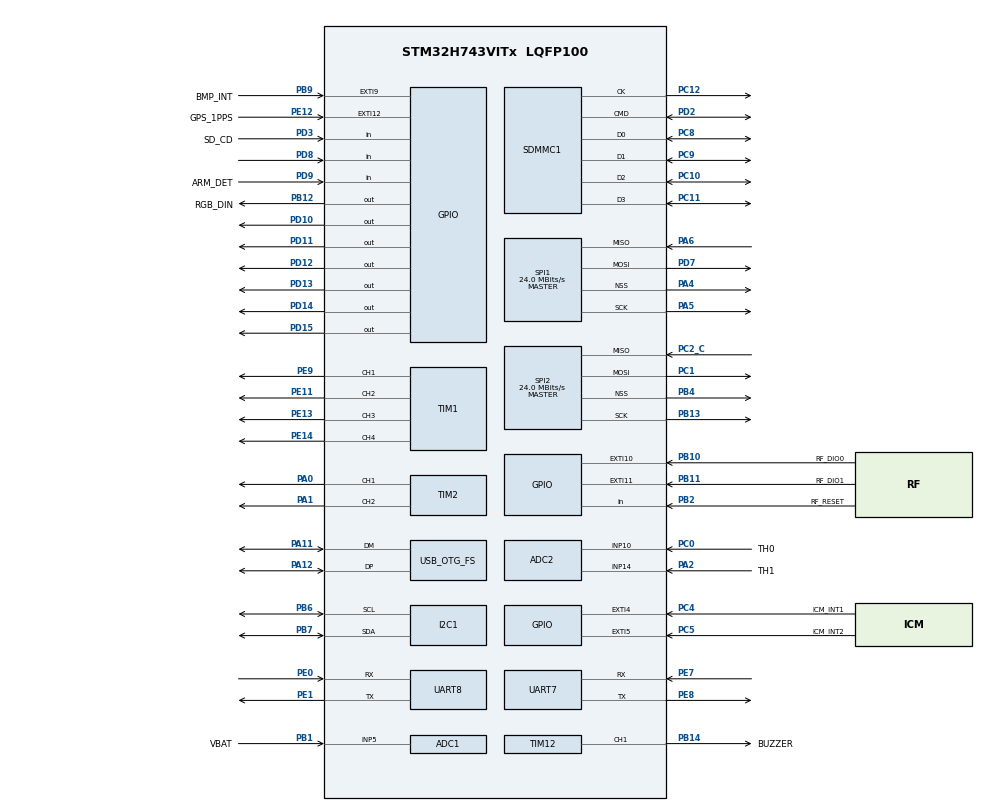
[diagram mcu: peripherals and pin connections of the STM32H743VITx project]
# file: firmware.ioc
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ADC1.Channel-2\#ChannelRegularConversion=ADC_CHANNEL_5
ADC1.ClockPrescaler=ADC_CLOCK_ASYNC_DIV4
ADC1.NbrOfConversionFlag=1
ADC1.OffsetNumber-2\#ChannelRegularConversion=ADC_OFFSET_NONE
ADC1.OffsetSignedSaturation-2\#ChannelRegularConversion=DISABLE
ADC1.Rank-2\#ChannelRegularConversion=1
ADC1.SamplingTime-2\#ChannelRegularConversion=ADC_SAMPLETIME_1CYCLE_5
ADC1.master=1
ADC2.Channel-3\#ChannelRegularConversion=ADC_CHANNEL_10
ADC2.ClockPrescaler=ADC_CLOCK_ASYNC_DIV4
ADC2.NbrOfConversionFlag=1
ADC2.OffsetNumber-3\#ChannelRegularConversion=ADC_OFFSET_NONE
ADC2.OffsetSignedSaturation-3\#ChannelRegularConversion=DISABLE
ADC2.Rank-3\#ChannelRegularConversion=1
ADC2.SamplingTime-3\#ChannelRegularConversion=ADC_SAMPLETIME_1CYCLE_5
CORTEX_M7.default_mode_Activation=1
FATFS.BSP.number=1
FATFS0.BSP.STBoard=false
FATFS0.BSP.api=Unknown
FATFS0.BSP.instance=PD3
FATFS0.BSP.ip=GPIO
FATFS0.BSP.mode=Input
FATFS0.BSP.name=Detect_SDIO
FATFS0.BSP.solution=PD3
I2C1.Timing=0x00707CBB
Mcu.Family=STM32H7
Mcu.Name=STM32H743VITx
Mcu.Package=LQFP100
NVIC.OTG_FS_IRQn=true\:0\:0\:false\:false\:true\:false\:true\:true
NVIC.PriorityGroup=NVIC_PRIORITYGROUP_4
PA0.Signal=S_TIM2_CH1_ETR
PA1.Signal=S_TIM2_CH2
PA11.Mode=Device_Only
PA11.Signal=USB_OTG_FS_DM
PA12.Mode=Device_Only
PA12.Signal=USB_OTG_FS_DP
PA13\ (JTMS/SWDIO).Signal=DEBUG_JTMS-SWDIO
PA14\ (JTCK/SWCLK).Signal=DEBUG_JTCK-SWCLK
PA2.GPIO_Label=TH1
PA2.Signal=ADCx_INP14
PA4.Mode=NSS_Signal_Hard_Output
PA4.Signal=SPI1_NSS
PA5.Mode=Full_Duplex_Master
PA5.Signal=SPI1_SCK
PA6.Mode=Full_Duplex_Master
PA6.Signal=SPI1_MISO
PB1.GPIO_Label=VBAT
PB1.Signal=ADCx_INP5
PB10.GPIO_Label=RF_DIO0
PB10.Signal=GPXTI10
PB11.GPIO_Label=RF_DIO1
PB11.Signal=GPXTI11
PB12.GPIO_Label=RGB_DIN
PB12.Signal=GPIO_Output
PB13.Mode=Full_Duplex_Master
PB13.Signal=SPI2_SCK
PB14.GPIO_Label=BUZZER
PB14.Signal=S_TIM12_CH1
PB2.GPIO_Label=RF_RESET
PB2.Signal=GPIO_Input
PB4\ (NJTRST).Mode=NSS_Signal_Hard_Output
PB4\ (NJTRST).Signal=SPI2_NSS
PB6.Mode=I2C
PB6.Signal=I2C1_SCL
PB7.Mode=I2C
PB7.Signal=I2C1_SDA
PB9.GPIO_Label=BMP_INT
PB9.Signal=GPXTI9
PC0.GPIO_Label=TH0
PC0.Signal=ADCx_INP10
PC1.Mode=Full_Duplex_Master
PC1.Signal=SPI2_MOSI
PC10.Mode=SD_4_bits_Wide_bus
PC10.Signal=SDMMC1_D2
PC11.Mode=SD_4_bits_Wide_bus
PC11.Signal=SDMMC1_D3
PC12.Mode=SD_4_bits_Wide_bus
PC12.Signal=SDMMC1_CK
PC14-OSC32_IN\ (OSC32_IN).Mode=LSE-External-Oscillator
PC14-OSC32_IN\ (OSC32_IN).Signal=RCC_OSC32_IN
PC15-OSC32_OUT\ (OSC32_OUT).Mode=LSE-External-Oscillator
PC15-OSC32_OUT\ (OSC32_OUT).Signal=RCC_OSC32_OUT
PC2_C.Mode=Full_Duplex_Master
PC2_C.Signal=SPI2_MISO
PC4.GPIO_Label=ICM_INT1
PC4.Signal=GPXTI4
PC5.GPIO_Label=ICM_INT2
PC5.Signal=GPXTI5
PC8.Mode=SD_4_bits_Wide_bus
PC8.Signal=SDMMC1_D0
PC9.Mode=SD_4_bits_Wide_bus
PC9.Signal=SDMMC1_D1
PD10.Signal=GPIO_Output
PD11.Signal=GPIO_Output
PD12.Signal=GPIO_Output
PD13.Signal=GPIO_Output
PD14.Signal=GPIO_Output
PD15.Signal=GPIO_Output
PD2.Mode=SD_4_bits_Wide_bus
PD2.Signal=SDMMC1_CMD
PD3.GPIO_Label=SD_CD
PD3.Signal=GPIO_Input
PD7.Mode=Full_Duplex_Master
PD7.Signal=SPI1_MOSI
PD8.Signal=GPIO_Input
PD9.GPIO_Label=ARM_DET
PD9.Signal=GPIO_Input
PE0.Mode=Asynchronous
PE0.Signal=UART8_RX
PE1.Mode=Asynchronous
PE1.Signal=UART8_TX
PE11.Signal=S_TIM1_CH2
PE12.GPIO_Label=GPS_1PPS
PE12.Signal=GPXTI12
PE13.Signal=S_TIM1_CH3
PE14.Signal=S_TIM1_CH4
PE7.Mode=Asynchronous
PE7.Signal=UART7_RX
PE8.Mode=Asynchronous
PE8.Signal=UART7_TX
PE9.Signal=S_TIM1_CH1
PH0-OSC_IN\ (PH0).Mode=HSE-External-Oscillator
PH0-OSC_IN\ (PH0).Signal=RCC_OSC_IN
PH1-OSC_OUT\ (PH1).Mode=HSE-External-Oscillator
PH1-OSC_OUT\ (PH1).Signal=RCC_OSC_OUT
ProjectManager.HeapSize=0x200
ProjectManager.StackSize=0x400
ProjectManager.TargetToolchain=Makefile
RCC.ADCFreq_Value=75000000
RCC.APB1Freq_Value=32000000
RCC.APB2Freq_Value=64000000
RCC.APB3Freq_Value=64000000
RCC.APB4Freq_Value=64000000
RCC.CortexFreq_Value=64000000
RCC.D2PPRE1=RCC_APB1_DIV2
RCC.DIVM1=5
RCC.DIVM2=2
RCC.DIVN1=48
RCC.DIVN2=12
RCC.DIVQ1=5
RCC.HCLKFreq_Value=64000000
RCC.PLL2FRACN=0
RCC.PLL3FRACN=0
RCC.PLLFRACN=0
RCC.SYSCLKFreq_VALUE=64000000
RCC.USBFreq_Value=48000000
SH.ADCx_INP10.0=ADC2_INP10,IN10-Single-Ended
SH.ADCx_INP10.1=ADC1_INP10
SH.ADCx_INP14.0=ADC2_INP14,IN14-Single-Ended
SH.ADCx_INP5.0=ADC1_INP5,IN5-Single-Ended
SH.S_TIM12_CH1.0=TIM12_CH1,PWM Generation1 CH1
SH.S_TIM1_CH1.0=TIM1_CH1,PWM Generation1 CH1
SH.S_TIM1_CH2.0=TIM1_CH2,PWM Generation2 CH2
SH.S_TIM1_CH3.0=TIM1_CH3,PWM Generation3 CH3
SH.S_TIM1_CH4.0=TIM1_CH4,PWM Generation4 CH4
SH.S_TIM2_CH1_ETR.0=TIM2_CH1,PWM Generation1 CH1
SH.S_TIM2_CH2.0=TIM2_CH2,PWM Generation2 CH2
SPI1.CalculateBaudRate=24.0 MBits/s
SPI1.Direction=SPI_DIRECTION_2LINES
SPI1.Mode=SPI_MODE_MASTER
SPI1.VirtualNSS=VM_NSSHARD
SPI1.VirtualType=VM_MASTER
SPI2.CalculateBaudRate=24.0 MBits/s
SPI2.Direction=SPI_DIRECTION_2LINES
SPI2.Mode=SPI_MODE_MASTER
SPI2.VirtualNSS=VM_NSSHARD
SPI2.VirtualType=VM_MASTER
TIM1.Channel-PWM\ Generation1\ CH1=TIM_CHANNEL_1
TIM1.Channel-PWM\ Generation2\ CH2=TIM_CHANNEL_2
TIM1.Channel-PWM\ Generation3\ CH3=TIM_CHANNEL_3
TIM1.Channel-PWM\ Generation4\ CH4=TIM_CHANNEL_4
TIM12.Channel-PWM\ Generation1\ CH1=TIM_CHANNEL_1
TIM2.Channel-PWM\ Generation1\ CH1=TIM_CHANNEL_1
TIM2.Channel-PWM\ Generation2\ CH2=TIM_CHANNEL_2
USB_DEVICE.CLASS_NAME_FS=CDC
USB_DEVICE.VirtualMode-CDC_FS=Cdc
USB_DEVICE.VirtualModeFS=Cdc_FS
USB_OTG_FS.VirtualMode=Device_Only
VP_FATFS_VS_SDIO.Mode=SDIO
VP_MEMORYMAP_VS_MEMORYMAP.Mode=CurAppReg
VP_TIM1_VS_ClockSourceINT.Mode=Internal
VP_TIM2_VS_ClockSourceINT.Mode=Internal
VP_USB_DEVICE_VS_USB_DEVICE_CDC_FS.Mode=CDC_FS
board=custom

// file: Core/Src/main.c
/* USER CODE BEGIN Header */
/**
  ******************************************************************************
  * @file           : main.c
  * @brief          : Main program body
  ******************************************************************************
  * @attention
  *
  * Copyright (c) 2025 STMicroelectronics.
  * All rights reserved.
  *
  * This software is licensed under terms that can be found in the LICENSE file
  * in the root directory of this software component.
  * If no LICENSE file comes with this software, it is provided AS-IS.
  *
  ******************************************************************************
  */
/* USER CODE END Header */
#include "main.h"
#include "fatfs.h"
#include "usb_device.h"

/* USER CODE BEGIN Includes */
#include "logging.h"

/* USER CODE END Includes */

ADC_HandleTypeDef hadc1;
ADC_HandleTypeDef hadc2;

I2C_HandleTypeDef hi2c1;

SD_HandleTypeDef hsd1;

SPI_HandleTypeDef hspi1;
SPI_HandleTypeDef hspi2;

TIM_HandleTypeDef htim1;
TIM_HandleTypeDef htim2;
TIM_HandleTypeDef htim12;

UART_HandleTypeDef huart7;
UART_HandleTypeDef huart8;

void SystemClock_Config(void);
void PeriphCommonClock_Config(void);
static void MPU_Config(void);
static void MX_GPIO_Init(void);
static void MX_I2C1_Init(void);
static void MX_SDMMC1_SD_Init(void);
static void MX_SPI1_Init(void);
static void MX_SPI2_Init(void);
static void MX_TIM1_Init(void);
static void MX_TIM2_Init(void);
static void MX_TIM12_Init(void);
static void MX_UART7_Init(void);
static void MX_UART8_Init(void);
static void MX_ADC1_Init(void);
static void MX_ADC2_Init(void);

int main(void)
{

  /* MPU Configuration--------------------------------------------------------*/
  MPU_Config();

  /* MCU Configuration--------------------------------------------------------*/

  /* Reset of all peripherals, Initializes the Flash interface and the Systick. */
  HAL_Init();

  /* Configure the system clock */
  SystemClock_Config();

  /* Configure the peripherals common clocks */
  PeriphCommonClock_Config();

  /* Initialize all configured peripherals */
  MX_GPIO_Init();
  MX_I2C1_Init();
  MX_SDMMC1_SD_Init();
  MX_SPI1_Init();
  MX_SPI2_Init();
  MX_TIM1_Init();
  MX_TIM2_Init();
  MX_TIM12_Init();
  MX_UART7_Init();
  MX_UART8_Init();
  MX_ADC1_Init();
  MX_ADC2_Init();
  MX_USB_DEVICE_Init();
  MX_FATFS_Init();
  /* USER CODE BEGIN 2 */
  logging_init();
  /* USER CODE END 2 */

  /* Infinite loop */
  while (1)
  {

  }
}

void SystemClock_Config(void)
{
  RCC_OscInitTypeDef RCC_OscInitStruct = {0};
  RCC_ClkInitTypeDef RCC_ClkInitStruct = {0};

  /** Supply configuration update enable
  */
  HAL_PWREx_ConfigSupply(PWR_LDO_SUPPLY);

  /** Configure the main internal regulator output voltage
  */
  __HAL_PWR_VOLTAGESCALING_CONFIG(PWR_REGULATOR_VOLTAGE_SCALE3);

  while(!__HAL_PWR_GET_FLAG(PWR_FLAG_VOSRDY)) {}

  /** Initializes the RCC Oscillators according to the specified parameters
  * in the RCC_OscInitTypeDef structure.
  */
  RCC_OscInitStruct.OscillatorType = RCC_OSCILLATORTYPE_HSI|RCC_OSCILLATORTYPE_HSE;
  RCC_OscInitStruct.HSEState = RCC_HSE_ON;
  RCC_OscInitStruct.HSIState = RCC_HSI_DIV1;
  RCC_OscInitStruct.HSICalibrationValue = RCC_HSICALIBRATION_DEFAULT;
  RCC_OscInitStruct.PLL.PLLState = RCC_PLL_ON;
  RCC_OscInitStruct.PLL.PLLSource = RCC_PLLSOURCE_HSE;
  RCC_OscInitStruct.PLL.PLLM = 5;
  RCC_OscInitStruct.PLL.PLLN = 48;
  RCC_OscInitStruct.PLL.PLLP = 2;
  RCC_OscInitStruct.PLL.PLLQ = 5;
  RCC_OscInitStruct.PLL.PLLR = 2;
  RCC_OscInitStruct.PLL.PLLRGE = RCC_PLL1VCIRANGE_2;
  RCC_OscInitStruct.PLL.PLLVCOSEL = RCC_PLL1VCOWIDE;
  RCC_OscInitStruct.PLL.PLLFRACN = 0;
  if (HAL_RCC_OscConfig(&RCC_OscInitStruct) != HAL_OK)
  {
    Error_Handler();
  }

  /** Initializes the CPU, AHB and APB buses clocks
  */
  RCC_ClkInitStruct.ClockType = RCC_CLOCKTYPE_HCLK|RCC_CLOCKTYPE_SYSCLK
                              |RCC_CLOCKTYPE_PCLK1|RCC_CLOCKTYPE_PCLK2
                              |RCC_CLOCKTYPE_D3PCLK1|RCC_CLOCKTYPE_D1PCLK1;
  RCC_ClkInitStruct.SYSCLKSource = RCC_SYSCLKSOURCE_HSI;
  RCC_ClkInitStruct.SYSCLKDivider = RCC_SYSCLK_DIV1;
  RCC_ClkInitStruct.AHBCLKDivider = RCC_HCLK_DIV1;
  RCC_ClkInitStruct.APB3CLKDivider = RCC_APB3_DIV1;
  RCC_ClkInitStruct.APB1CLKDivider = RCC_APB1_DIV2;
  RCC_ClkInitStruct.APB2CLKDivider = RCC_APB2_DIV1;
  RCC_ClkInitStruct.APB4CLKDivider = RCC_APB4_DIV1;

  if (HAL_RCC_ClockConfig(&RCC_ClkInitStruct, FLASH_LATENCY_1) != HAL_OK)
  {
    Error_Handler();
  }
}

void PeriphCommonClock_Config(void)
{
  RCC_PeriphCLKInitTypeDef PeriphClkInitStruct = {0};

  /** Initializes the peripherals clock
  */
  PeriphClkInitStruct.PeriphClockSelection = RCC_PERIPHCLK_ADC;
  PeriphClkInitStruct.PLL2.PLL2M = 2;
  PeriphClkInitStruct.PLL2.PLL2N = 12;
  PeriphClkInitStruct.PLL2.PLL2P = 2;
  PeriphClkInitStruct.PLL2.PLL2Q = 2;
  PeriphClkInitStruct.PLL2.PLL2R = 2;
  PeriphClkInitStruct.PLL2.PLL2RGE = RCC_PLL2VCIRANGE_3;
  PeriphClkInitStruct.PLL2.PLL2VCOSEL = RCC_PLL2VCOMEDIUM;
  PeriphClkInitStruct.PLL2.PLL2FRACN = 0;
  PeriphClkInitStruct.AdcClockSelection = RCC_ADCCLKSOURCE_PLL2;
  if (HAL_RCCEx_PeriphCLKConfig(&PeriphClkInitStruct) != HAL_OK)
  {
    Error_Handler();
  }
}

static void MX_ADC1_Init(void)
{

  ADC_MultiModeTypeDef multimode = {0};
  ADC_ChannelConfTypeDef sConfig = {0};

  /** Common config
  */
  hadc1.Instance = ADC1;
  hadc1.Init.ClockPrescaler = ADC_CLOCK_ASYNC_DIV4;
  hadc1.Init.Resolution = ADC_RESOLUTION_16B;
  hadc1.Init.ScanConvMode = ADC_SCAN_DISABLE;
  hadc1.Init.EOCSelection = ADC_EOC_SINGLE_CONV;
  hadc1.Init.LowPowerAutoWait = DISABLE;
  hadc1.Init.ContinuousConvMode = DISABLE;
  hadc1.Init.NbrOfConversion = 1;
  hadc1.Init.DiscontinuousConvMode = DISABLE;
  hadc1.Init.ExternalTrigConv = ADC_SOFTWARE_START;
  hadc1.Init.ExternalTrigConvEdge = ADC_EXTERNALTRIGCONVEDGE_NONE;
  hadc1.Init.ConversionDataManagement = ADC_CONVERSIONDATA_DR;
  hadc1.Init.Overrun = ADC_OVR_DATA_PRESERVED;
  hadc1.Init.LeftBitShift = ADC_LEFTBITSHIFT_NONE;
  hadc1.Init.OversamplingMode = DISABLE;
  hadc1.Init.Oversampling.Ratio = 1;
  if (HAL_ADC_Init(&hadc1) != HAL_OK)
  {
    Error_Handler();
  }

  /** Configure the ADC multi-mode
  */
  multimode.Mode = ADC_MODE_INDEPENDENT;
  if (HAL_ADCEx_MultiModeConfigChannel(&hadc1, &multimode) != HAL_OK)
  {
    Error_Handler();
  }

  /** Configure Regular Channel
  */
  sConfig.Channel = ADC_CHANNEL_5;
  sConfig.Rank = ADC_REGULAR_RANK_1;
  sConfig.SamplingTime = ADC_SAMPLETIME_1CYCLE_5;
  sConfig.SingleDiff = ADC_SINGLE_ENDED;
  sConfig.OffsetNumber = ADC_OFFSET_NONE;
  sConfig.Offset = 0;
  sConfig.OffsetSignedSaturation = DISABLE;
  if (HAL_ADC_ConfigChannel(&hadc1, &sConfig) != HAL_OK)
  {
    Error_Handler();
  }

}

static void MX_ADC2_Init(void)
{

  ADC_ChannelConfTypeDef sConfig = {0};

  /** Common config
  */
  hadc2.Instance = ADC2;
  hadc2.Init.ClockPrescaler = ADC_CLOCK_ASYNC_DIV4;
  hadc2.Init.Resolution = ADC_RESOLUTION_16B;
  hadc2.Init.ScanConvMode = ADC_SCAN_DISABLE;
  hadc2.Init.EOCSelection = ADC_EOC_SINGLE_CONV;
  hadc2.Init.LowPowerAutoWait = DISABLE;
  hadc2.Init.ContinuousConvMode = DISABLE;
  hadc2.Init.NbrOfConversion = 1;
  hadc2.Init.DiscontinuousConvMode = DISABLE;
  hadc2.Init.ExternalTrigConv = ADC_SOFTWARE_START;
  hadc2.Init.ExternalTrigConvEdge = ADC_EXTERNALTRIGCONVEDGE_NONE;
  hadc2.Init.ConversionDataManagement = ADC_CONVERSIONDATA_DR;
  hadc2.Init.Overrun = ADC_OVR_DATA_PRESERVED;
  hadc2.Init.LeftBitShift = ADC_LEFTBITSHIFT_NONE;
  hadc2.Init.OversamplingMode = DISABLE;
  hadc2.Init.Oversampling.Ratio = 1;
  if (HAL_ADC_Init(&hadc2) != HAL_OK)
  {
    Error_Handler();
  }

  /** Configure Regular Channel
  */
  sConfig.Channel = ADC_CHANNEL_10;
  sConfig.Rank = ADC_REGULAR_RANK_1;
  sConfig.SamplingTime = ADC_SAMPLETIME_1CYCLE_5;
  sConfig.SingleDiff = ADC_SINGLE_ENDED;
  sConfig.OffsetNumber = ADC_OFFSET_NONE;
  sConfig.Offset = 0;
  sConfig.OffsetSignedSaturation = DISABLE;
  if (HAL_ADC_ConfigChannel(&hadc2, &sConfig) != HAL_OK)
  {
    Error_Handler();
  }

}

static void MX_I2C1_Init(void)
{

  hi2c1.Instance = I2C1;
  hi2c1.Init.Timing = 0x00707CBB;
  hi2c1.Init.OwnAddress1 = 0;
  hi2c1.Init.AddressingMode = I2C_ADDRESSINGMODE_7BIT;
  hi2c1.Init.DualAddressMode = I2C_DUALADDRESS_DISABLE;
  hi2c1.Init.OwnAddress2 = 0;
  hi2c1.Init.OwnAddress2Masks = I2C_OA2_NOMASK;
  hi2c1.Init.GeneralCallMode = I2C_GENERALCALL_DISABLE;
  hi2c1.Init.NoStretchMode = I2C_NOSTRETCH_DISABLE;
  if (HAL_I2C_Init(&hi2c1) != HAL_OK)
  {
    Error_Handler();
  }

  /** Configure Analogue filter
  */
  if (HAL_I2CEx_ConfigAnalogFilter(&hi2c1, I2C_ANALOGFILTER_ENABLE) != HAL_OK)
  {
    Error_Handler();
  }

  /** Configure Digital filter
  */
  if (HAL_I2CEx_ConfigDigitalFilter(&hi2c1, 0) != HAL_OK)
  {
    Error_Handler();
  }

}

static void MX_SDMMC1_SD_Init(void)
{

  hsd1.Instance = SDMMC1;
  hsd1.Init.ClockEdge = SDMMC_CLOCK_EDGE_RISING;
  hsd1.Init.ClockPowerSave = SDMMC_CLOCK_POWER_SAVE_DISABLE;
  hsd1.Init.BusWide = SDMMC_BUS_WIDE_4B;
  hsd1.Init.HardwareFlowControl = SDMMC_HARDWARE_FLOW_CONTROL_DISABLE;
  hsd1.Init.ClockDiv = 0;
  if (HAL_SD_Init(&hsd1) != HAL_OK)
  {
    Error_Handler();
  }

}

static void MX_SPI1_Init(void)
{

  /* SPI1 parameter configuration*/
  hspi1.Instance = SPI1;
  hspi1.Init.Mode = SPI_MODE_MASTER;
  hspi1.Init.Direction = SPI_DIRECTION_2LINES;
  hspi1.Init.DataSize = SPI_DATASIZE_4BIT;
  hspi1.Init.CLKPolarity = SPI_POLARITY_LOW;
  hspi1.Init.CLKPhase = SPI_PHASE_1EDGE;
  hspi1.Init.NSS = SPI_NSS_HARD_OUTPUT;
  hspi1.Init.BaudRatePrescaler = SPI_BAUDRATEPRESCALER_2;
  hspi1.Init.FirstBit = SPI_FIRSTBIT_MSB;
  hspi1.Init.TIMode = SPI_TIMODE_DISABLE;
  hspi1.Init.CRCCalculation = SPI_CRCCALCULATION_DISABLE;
  hspi1.Init.CRCPolynomial = 0x0;
  hspi1.Init.NSSPMode = SPI_NSS_PULSE_ENABLE;
  hspi1.Init.NSSPolarity = SPI_NSS_POLARITY_LOW;
  hspi1.Init.FifoThreshold = SPI_FIFO_THRESHOLD_01DATA;
  hspi1.Init.TxCRCInitializationPattern = SPI_CRC_INITIALIZATION_ALL_ZERO_PATTERN;
  hspi1.Init.RxCRCInitializationPattern = SPI_CRC_INITIALIZATION_ALL_ZERO_PATTERN;
  hspi1.Init.MasterSSIdleness = SPI_MASTER_SS_IDLENESS_00CYCLE;
  hspi1.Init.MasterInterDataIdleness = SPI_MASTER_INTERDATA_IDLENESS_00CYCLE;
  hspi1.Init.MasterReceiverAutoSusp = SPI_MASTER_RX_AUTOSUSP_DISABLE;
  hspi1.Init.MasterKeepIOState = SPI_MASTER_KEEP_IO_STATE_DISABLE;
  hspi1.Init.IOSwap = SPI_IO_SWAP_DISABLE;
  if (HAL_SPI_Init(&hspi1) != HAL_OK)
  {
    Error_Handler();
  }

}

static void MX_SPI2_Init(void)
{

  /* SPI2 parameter configuration*/
  hspi2.Instance = SPI2;
  hspi2.Init.Mode = SPI_MODE_MASTER;
  hspi2.Init.Direction = SPI_DIRECTION_2LINES;
  hspi2.Init.DataSize = SPI_DATASIZE_4BIT;
  hspi2.Init.CLKPolarity = SPI_POLARITY_LOW;
  hspi2.Init.CLKPhase = SPI_PHASE_1EDGE;
  hspi2.Init.NSS = SPI_NSS_HARD_OUTPUT;
  hspi2.Init.BaudRatePrescaler = SPI_BAUDRATEPRESCALER_2;
  hspi2.Init.FirstBit = SPI_FIRSTBIT_MSB;
  hspi2.Init.TIMode = SPI_TIMODE_DISABLE;
  hspi2.Init.CRCCalculation = SPI_CRCCALCULATION_DISABLE;
  hspi2.Init.CRCPolynomial = 0x0;
  hspi2.Init.NSSPMode = SPI_NSS_PULSE_ENABLE;
  hspi2.Init.NSSPolarity = SPI_NSS_POLARITY_LOW;
  hspi2.Init.FifoThreshold = SPI_FIFO_THRESHOLD_01DATA;
  hspi2.Init.TxCRCInitializationPattern = SPI_CRC_INITIALIZATION_ALL_ZERO_PATTERN;
  hspi2.Init.RxCRCInitializationPattern = SPI_CRC_INITIALIZATION_ALL_ZERO_PATTERN;
  hspi2.Init.MasterSSIdleness = SPI_MASTER_SS_IDLENESS_00CYCLE;
  hspi2.Init.MasterInterDataIdleness = SPI_MASTER_INTERDATA_IDLENESS_00CYCLE;
  hspi2.Init.MasterReceiverAutoSusp = SPI_MASTER_RX_AUTOSUSP_DISABLE;
  hspi2.Init.MasterKeepIOState = SPI_MASTER_KEEP_IO_STATE_DISABLE;
  hspi2.Init.IOSwap = SPI_IO_SWAP_DISABLE;
  if (HAL_SPI_Init(&hspi2) != HAL_OK)
  {
    Error_Handler();
  }

}

static void MX_TIM1_Init(void)
{

  TIM_ClockConfigTypeDef sClockSourceConfig = {0};
  TIM_MasterConfigTypeDef sMasterConfig = {0};
  TIM_OC_InitTypeDef sConfigOC = {0};
  TIM_BreakDeadTimeConfigTypeDef sBreakDeadTimeConfig = {0};

  htim1.Instance = TIM1;
  htim1.Init.Prescaler = 0;
  htim1.Init.CounterMode = TIM_COUNTERMODE_UP;
  htim1.Init.Period = 65535;
  htim1.Init.ClockDivision = TIM_CLOCKDIVISION_DIV1;
  htim1.Init.RepetitionCounter = 0;
  htim1.Init.AutoReloadPreload = TIM_AUTORELOAD_PRELOAD_DISABLE;
  if (HAL_TIM_Base_Init(&htim1) != HAL_OK)
  {
    Error_Handler();
  }
  sClockSourceConfig.ClockSource = TIM_CLOCKSOURCE_INTERNAL;
  if (HAL_TIM_ConfigClockSource(&htim1, &sClockSourceConfig) != HAL_OK)
  {
    Error_Handler();
  }
  if (HAL_TIM_PWM_Init(&htim1) != HAL_OK)
  {
    Error_Handler();
  }
  sMasterConfig.MasterOutputTrigger = TIM_TRGO_RESET;
  sMasterConfig.MasterOutputTrigger2 = TIM_TRGO2_RESET;
  sMasterConfig.MasterSlaveMode = TIM_MASTERSLAVEMODE_DISABLE;
  if (HAL_TIMEx_MasterConfigSynchronization(&htim1, &sMasterConfig) != HAL_OK)
  {
    Error_Handler();
  }
  sConfigOC.OCMode = TIM_OCMODE_PWM1;
  sConfigOC.Pulse = 0;
  sConfigOC.OCPolarity = TIM_OCPOLARITY_HIGH;
  sConfigOC.OCNPolarity = TIM_OCNPOLARITY_HIGH;
  sConfigOC.OCFastMode = TIM_OCFAST_DISABLE;
  sConfigOC.OCIdleState = TIM_OCIDLESTATE_RESET;
  sConfigOC.OCNIdleState = TIM_OCNIDLESTATE_RESET;
  if (HAL_TIM_PWM_ConfigChannel(&htim1, &sConfigOC, TIM_CHANNEL_1) != HAL_OK)
  {
    Error_Handler();
  }
  if (HAL_TIM_PWM_ConfigChannel(&htim1, &sConfigOC, TIM_CHANNEL_2) != HAL_OK)
  {
    Error_Handler();
  }
  if (HAL_TIM_PWM_ConfigChannel(&htim1, &sConfigOC, TIM_CHANNEL_3) != HAL_OK)
  {
    Error_Handler();
  }
  if (HAL_TIM_PWM_ConfigChannel(&htim1, &sConfigOC, TIM_CHANNEL_4) != HAL_OK)
  {
    Error_Handler();
  }
  sBreakDeadTimeConfig.OffStateRunMode = TIM_OSSR_DISABLE;
  sBreakDeadTimeConfig.OffStateIDLEMode = TIM_OSSI_DISABLE;
  sBreakDeadTimeConfig.LockLevel = TIM_LOCKLEVEL_OFF;
  sBreakDeadTimeConfig.DeadTime = 0;
  sBreakDeadTimeConfig.BreakState = TIM_BREAK_DISABLE;
  sBreakDeadTimeConfig.BreakPolarity = TIM_BREAKPOLARITY_HIGH;
  sBreakDeadTimeConfig.BreakFilter = 0;
  sBreakDeadTimeConfig.Break2State = TIM_BREAK2_DISABLE;
  sBreakDeadTimeConfig.Break2Polarity = TIM_BREAK2POLARITY_HIGH;
  sBreakDeadTimeConfig.Break2Filter = 0;
  sBreakDeadTimeConfig.AutomaticOutput = TIM_AUTOMATICOUTPUT_DISABLE;
  if (HAL_TIMEx_ConfigBreakDeadTime(&htim1, &sBreakDeadTimeConfig) != HAL_OK)
  {
    Error_Handler();
  }
  HAL_TIM_MspPostInit(&htim1);

}

static void MX_TIM2_Init(void)
{

  TIM_ClockConfigTypeDef sClockSourceConfig = {0};
  TIM_MasterConfigTypeDef sMasterConfig = {0};
  TIM_OC_InitTypeDef sConfigOC = {0};

  htim2.Instance = TIM2;
  htim2.Init.Prescaler = 0;
  htim2.Init.CounterMode = TIM_COUNTERMODE_UP;
  htim2.Init.Period = 4294967295;
  htim2.Init.ClockDivision = TIM_CLOCKDIVISION_DIV1;
  htim2.Init.AutoReloadPreload = TIM_AUTORELOAD_PRELOAD_DISABLE;
  if (HAL_TIM_Base_Init(&htim2) != HAL_OK)
  {
    Error_Handler();
  }
  sClockSourceConfig.ClockSource = TIM_CLOCKSOURCE_INTERNAL;
  if (HAL_TIM_ConfigClockSource(&htim2, &sClockSourceConfig) != HAL_OK)
  {
    Error_Handler();
  }
  if (HAL_TIM_PWM_Init(&htim2) != HAL_OK)
  {
    Error_Handler();
  }
  sMasterConfig.MasterOutputTrigger = TIM_TRGO_RESET;
  sMasterConfig.MasterSlaveMode = TIM_MASTERSLAVEMODE_DISABLE;
  if (HAL_TIMEx_MasterConfigSynchronization(&htim2, &sMasterConfig) != HAL_OK)
  {
    Error_Handler();
  }
  sConfigOC.OCMode = TIM_OCMODE_PWM1;
  sConfigOC.Pulse = 0;
  sConfigOC.OCPolarity = TIM_OCPOLARITY_HIGH;
  sConfigOC.OCFastMode = TIM_OCFAST_DISABLE;
  if (HAL_TIM_PWM_ConfigChannel(&htim2, &sConfigOC, TIM_CHANNEL_1) != HAL_OK)
  {
    Error_Handler();
  }
  if (HAL_TIM_PWM_ConfigChannel(&htim2, &sConfigOC, TIM_CHANNEL_2) != HAL_OK)
  {
    Error_Handler();
  }
  HAL_TIM_MspPostInit(&htim2);

}

static void MX_TIM12_Init(void)
{

  TIM_MasterConfigTypeDef sMasterConfig = {0};
  TIM_OC_InitTypeDef sConfigOC = {0};

  htim12.Instance = TIM12;
  htim12.Init.Prescaler = 0;
  htim12.Init.CounterMode = TIM_COUNTERMODE_UP;
  htim12.Init.Period = 65535;
  htim12.Init.ClockDivision = TIM_CLOCKDIVISION_DIV1;
  htim12.Init.AutoReloadPreload = TIM_AUTORELOAD_PRELOAD_DISABLE;
  if (HAL_TIM_PWM_Init(&htim12) != HAL_OK)
  {
    Error_Handler();
  }
  sMasterConfig.MasterOutputTrigger = TIM_TRGO_RESET;
  sMasterConfig.MasterSlaveMode = TIM_MASTERSLAVEMODE_DISABLE;
  if (HAL_TIMEx_MasterConfigSynchronization(&htim12, &sMasterConfig) != HAL_OK)
  {
    Error_Handler();
  }
  sConfigOC.OCMode = TIM_OCMODE_PWM1;
  sConfigOC.Pulse = 0;
  sConfigOC.OCPolarity = TIM_OCPOLARITY_HIGH;
  sConfigOC.OCFastMode = TIM_OCFAST_DISABLE;
  if (HAL_TIM_PWM_ConfigChannel(&htim12, &sConfigOC, TIM_CHANNEL_1) != HAL_OK)
  {
    Error_Handler();
  }
  HAL_TIM_MspPostInit(&htim12);

}

static void MX_UART7_Init(void)
{

  huart7.Instance = UART7;
  huart7.Init.BaudRate = 115200;
  huart7.Init.WordLength = UART_WORDLENGTH_8B;
  huart7.Init.StopBits = UART_STOPBITS_1;
  huart7.Init.Parity = UART_PARITY_NONE;
  huart7.Init.Mode = UART_MODE_TX_RX;
  huart7.Init.HwFlowCtl = UART_HWCONTROL_NONE;
  huart7.Init.OverSampling = UART_OVERSAMPLING_16;
  huart7.Init.OneBitSampling = UART_ONE_BIT_SAMPLE_DISABLE;
  huart7.Init.ClockPrescaler = UART_PRESCALER_DIV1;
  huart7.AdvancedInit.AdvFeatureInit = UART_ADVFEATURE_NO_INIT;
  if (HAL_UART_Init(&huart7) != HAL_OK)
  {
    Error_Handler();
  }
  if (HAL_UARTEx_SetTxFifoThreshold(&huart7, UART_TXFIFO_THRESHOLD_1_8) != HAL_OK)
  {
    Error_Handler();
  }
  if (HAL_UARTEx_SetRxFifoThreshold(&huart7, UART_RXFIFO_THRESHOLD_1_8) != HAL_OK)
  {
    Error_Handler();
  }
  if (HAL_UARTEx_DisableFifoMode(&huart7) != HAL_OK)
  {
    Error_Handler();
  }

}

static void MX_UART8_Init(void)
{

  huart8.Instance = UART8;
  huart8.Init.BaudRate = 115200;
  huart8.Init.WordLength = UART_WORDLENGTH_8B;
  huart8.Init.StopBits = UART_STOPBITS_1;
  huart8.Init.Parity = UART_PARITY_NONE;
  huart8.Init.Mode = UART_MODE_TX_RX;
  huart8.Init.HwFlowCtl = UART_HWCONTROL_NONE;
  huart8.Init.OverSampling = UART_OVERSAMPLING_16;
  huart8.Init.OneBitSampling = UART_ONE_BIT_SAMPLE_DISABLE;
  huart8.Init.ClockPrescaler = UART_PRESCALER_DIV1;
  huart8.AdvancedInit.AdvFeatureInit = UART_ADVFEATURE_NO_INIT;
  if (HAL_UART_Init(&huart8) != HAL_OK)
  {
    Error_Handler();
  }
  if (HAL_UARTEx_SetTxFifoThreshold(&huart8, UART_TXFIFO_THRESHOLD_1_8) != HAL_OK)
  {
    Error_Handler();
  }
  if (HAL_UARTEx_SetRxFifoThreshold(&huart8, UART_RXFIFO_THRESHOLD_1_8) != HAL_OK)
  {
    Error_Handler();
  }
  if (HAL_UARTEx_DisableFifoMode(&huart8) != HAL_OK)
  {
    Error_Handler();
  }

}

static void MX_GPIO_Init(void)
{
  GPIO_InitTypeDef GPIO_InitStruct = {0};

  /* GPIO Ports Clock Enable */
  __HAL_RCC_GPIOC_CLK_ENABLE();
  __HAL_RCC_GPIOH_CLK_ENABLE();
  __HAL_RCC_GPIOA_CLK_ENABLE();
  __HAL_RCC_GPIOB_CLK_ENABLE();
  __HAL_RCC_GPIOE_CLK_ENABLE();
  __HAL_RCC_GPIOD_CLK_ENABLE();

  /*Configure GPIO pin Output Level */
  HAL_GPIO_WritePin(RGB_DIN_GPIO_Port, RGB_DIN_Pin, GPIO_PIN_RESET);

  /*Configure GPIO pin Output Level */
  HAL_GPIO_WritePin(GPIOD, GPIO_PIN_10|GPIO_PIN_11|GPIO_PIN_12|GPIO_PIN_13
                          |GPIO_PIN_14|GPIO_PIN_15, GPIO_PIN_RESET);

  /*Configure GPIO pins : ICM_INT1_Pin ICM_INT2_Pin */
  GPIO_InitStruct.Pin = ICM_INT1_Pin|ICM_INT2_Pin;
  GPIO_InitStruct.Mode = GPIO_MODE_IT_RISING;
  GPIO_InitStruct.Pull = GPIO_NOPULL;
  HAL_GPIO_Init(GPIOC, &GPIO_InitStruct);

  /*Configure GPIO pin : RF_RESET_Pin */
  GPIO_InitStruct.Pin = RF_RESET_Pin;
  GPIO_InitStruct.Mode = GPIO_MODE_INPUT;
  GPIO_InitStruct.Pull = GPIO_NOPULL;
  HAL_GPIO_Init(RF_RESET_GPIO_Port, &GPIO_InitStruct);

  /*Configure GPIO pin : GPS_1PPS_Pin */
  GPIO_InitStruct.Pin = GPS_1PPS_Pin;
  GPIO_InitStruct.Mode = GPIO_MODE_IT_RISING;
  GPIO_InitStruct.Pull = GPIO_NOPULL;
  HAL_GPIO_Init(GPS_1PPS_GPIO_Port, &GPIO_InitStruct);

  /*Configure GPIO pins : RF_DIO0_Pin RF_DIO1_Pin BMP_INT_Pin */
  GPIO_InitStruct.Pin = RF_DIO0_Pin|RF_DIO1_Pin|BMP_INT_Pin;
  GPIO_InitStruct.Mode = GPIO_MODE_IT_RISING;
  GPIO_InitStruct.Pull = GPIO_NOPULL;
  HAL_GPIO_Init(GPIOB, &GPIO_InitStruct);

  /*Configure GPIO pin : RGB_DIN_Pin */
  GPIO_InitStruct.Pin = RGB_DIN_Pin;
  GPIO_InitStruct.Mode = GPIO_MODE_OUTPUT_PP;
  GPIO_InitStruct.Pull = GPIO_NOPULL;
  GPIO_InitStruct.Speed = GPIO_SPEED_FREQ_LOW;
  HAL_GPIO_Init(RGB_DIN_GPIO_Port, &GPIO_InitStruct);

  /*Configure GPIO pins : PD8 ARM_DET_Pin SD_CD_Pin */
  GPIO_InitStruct.Pin = GPIO_PIN_8|ARM_DET_Pin|SD_CD_Pin;
  GPIO_InitStruct.Mode = GPIO_MODE_INPUT;
  GPIO_InitStruct.Pull = GPIO_NOPULL;
  HAL_GPIO_Init(GPIOD, &GPIO_InitStruct);

  /*Configure GPIO pins : PD10 PD11 PD12 PD13
                           PD14 PD15 */
  GPIO_InitStruct.Pin = GPIO_PIN_10|GPIO_PIN_11|GPIO_PIN_12|GPIO_PIN_13
                          |GPIO_PIN_14|GPIO_PIN_15;
  GPIO_InitStruct.Mode = GPIO_MODE_OUTPUT_PP;
  GPIO_InitStruct.Pull = GPIO_NOPULL;
  GPIO_InitStruct.Speed = GPIO_SPEED_FREQ_LOW;
  HAL_GPIO_Init(GPIOD, &GPIO_InitStruct);

}

 /* MPU Configuration */

void MPU_Config(void)
{
  MPU_Region_InitTypeDef MPU_InitStruct = {0};

  /* Disables the MPU */
  HAL_MPU_Disable();

  /** Initializes and configures the Region and the memory to be protected
  */
  MPU_InitStruct.Enable = MPU_REGION_ENABLE;
  MPU_InitStruct.Number = MPU_REGION_NUMBER0;
  MPU_InitStruct.BaseAddress = 0x0;
  MPU_InitStruct.Size = MPU_REGION_SIZE_4GB;
  MPU_InitStruct.SubRegionDisable = 0x87;
  MPU_InitStruct.TypeExtField = MPU_TEX_LEVEL0;
  MPU_InitStruct.AccessPermission = MPU_REGION_NO_ACCESS;
  MPU_InitStruct.DisableExec = MPU_INSTRUCTION_ACCESS_DISABLE;
  MPU_InitStruct.IsShareable = MPU_ACCESS_SHAREABLE;
  MPU_InitStruct.IsCacheable = MPU_ACCESS_NOT_CACHEABLE;
  MPU_InitStruct.IsBufferable = MPU_ACCESS_NOT_BUFFERABLE;

  HAL_MPU_ConfigRegion(&MPU_InitStruct);
  /* Enables the MPU */
  HAL_MPU_Enable(MPU_PRIVILEGED_DEFAULT);

}

void Error_Handler(void)
{
  __disable_irq();
  while (1)
  {
  }
}
